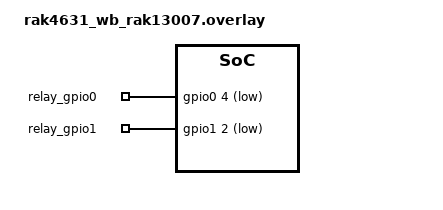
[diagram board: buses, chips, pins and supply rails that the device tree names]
/*
 * Copyright (c) 2025 Kenneth Lu
 *
 * SPDX-License-Identifier: Apache-2.0
 */
/ {
	aliases {
		relay0 = &relay_gpio0;
		relay1 = &relay_gpio1;
	};

	relay-gpio {
		compatible = "gpio-leds";
		relay_gpio0: relay_gpio0 {
			gpios = <&gpio0 4 GPIO_ACTIVE_LOW>;
		};

		relay_gpio1: relay_gpio1 {
			gpios = <&gpio1 2 GPIO_ACTIVE_LOW>;
		};
	};
};
